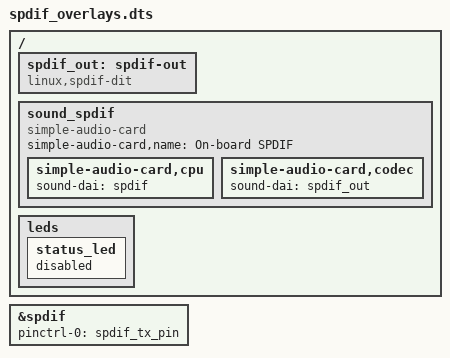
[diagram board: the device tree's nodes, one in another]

&spdif {
	pinctrl-names = "default";
	pinctrl-0 = <&spdif_tx_pin>;
	status = "okay";
};

/ {
	spdif_out: spdif-out {
		#sound-dai-cells = <0>;
		compatible = "linux,spdif-dit";
	};

	sound_spdif {
		compatible = "simple-audio-card";
		simple-audio-card,name = "On-board SPDIF";

		simple-audio-card,cpu {
			sound-dai = <&spdif>;
		};

		simple-audio-card,codec {
			sound-dai = <&spdif_out>;
		};
	};

	leds {
		status_led {
			status = "disabled";
		};
	};
};
